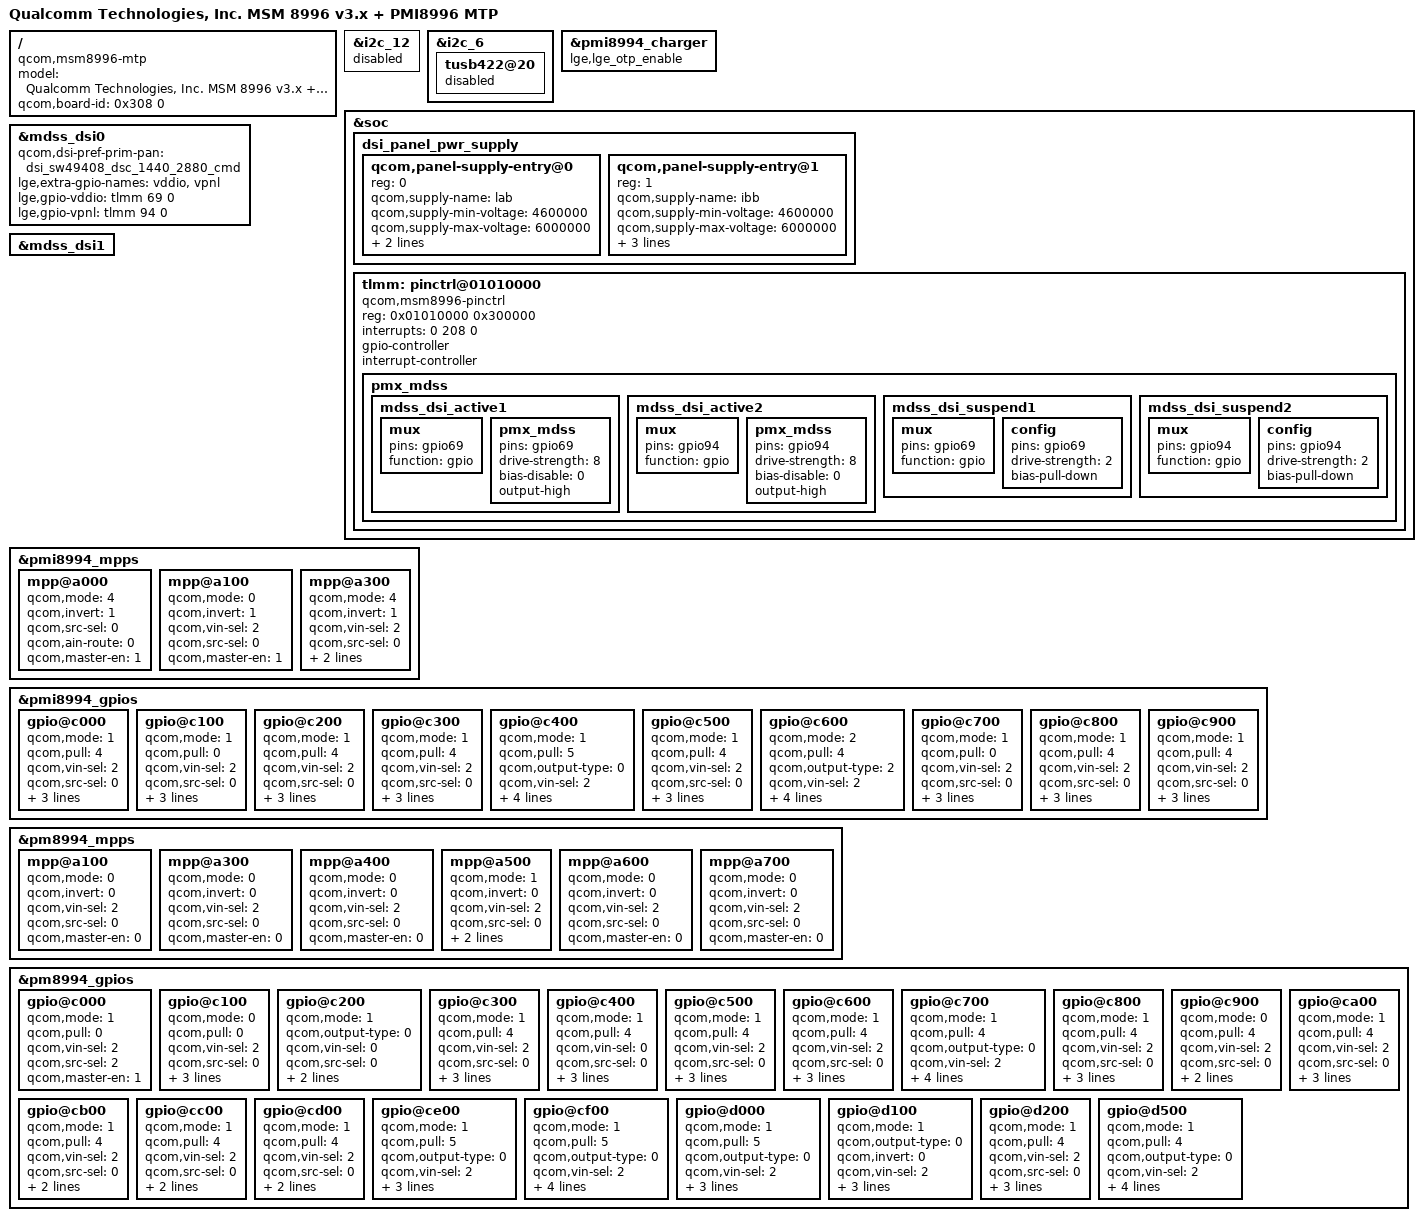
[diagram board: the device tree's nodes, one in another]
/* Copyright (c) 2015, The Linux Foundation. All rights reserved.
 *
 * This program is free software; you can redistribute it and/or modify
 * it under the terms of the GNU General Public License version 2 and
 * only version 2 as published by the Free Software Foundation.
 *
 * This program is distributed in the hope that it will be useful,
 * but WITHOUT ANY WARRANTY; without even the implied warranty of
 * MERCHANTABILITY or FITNESS FOR A PARTICULAR PURPOSE.  See the
 * GNU General Public License for more details.
 */


/dts-v1/;

#include "../../qcom/msm8996-v3.dtsi"
#include "../../qcom/msm-pmi8996.dtsi"
#include "msm8996-lucye_global_ldu.dtsi"
#include "msm8996-lucye_global_ldu-touch.dtsi"
#include "../msm8996-camera/msm8996-lucye-camera_rev-0.0.dtsi"
#include "../msm8996-lucye_storage_type/current_storage_type.dtsi"
#include "../msm8996-sound/msm8996-lucye-sound_rev-0_0.dtsi"
#include "../msm8996-lucye_sound_type/current_sound_type.dtsi"

/ {
	model = "Qualcomm Technologies, Inc. MSM 8996 v3.x + PMI8996 MTP";
	compatible = "qcom,msm8996-mtp", "qcom,msm8996", "qcom,mtp";
	qcom,board-id = <0x308 0>;
};

&i2c_12 {
	status = "disabled";
};

&i2c_6 {
	tusb422@20 {
		status = "disabled";
	};
};

&pmi8994_charger {
	/delete-property/qcom,external-typec;
	/delete-property/qcom,typec-psy-name;
};


/* Display Function */
&soc {
	dsi_panel_pwr_supply: dsi_panel_pwr_supply {
		#address-cells = <1>;
		#size-cells = <0>;

		qcom,panel-supply-entry@0 {
			reg = <0>;
			qcom,supply-name = "lab";
			qcom,supply-min-voltage = <4600000>;
			qcom,supply-max-voltage = <6000000>;
			qcom,supply-enable-load = <100000>;
			qcom,supply-disable-load = <100>;
		};

		qcom,panel-supply-entry@1 {
			reg = <1>;
			qcom,supply-name = "ibb";
			qcom,supply-min-voltage = <4600000>;
			qcom,supply-max-voltage = <6000000>;
			qcom,supply-enable-load = <100000>;
			qcom,supply-disable-load = <100>;
			qcom,supply-post-on-sleep = <20>;
		};
	};
};

&mdss_dsi0 {
	qcom,dsi-pref-prim-pan = <&dsi_sw49408_dsc_1440_2880_cmd>;
	lge,extra-gpio-names = "vddio", "vpnl";

	lge,gpio-vddio = <&tlmm 69 0>;
	lge,gpio-vpnl = <&tlmm 94 0>;
};

&mdss_dsi1 {
	/delete-property/cell-index;
};

/* pinctrl for Display function
 * GPIO69 : LCD_VDD_IO_EN
 * GPIO94 : LCD_VCL_EN
 */
&soc {
	tlmm: pinctrl@01010000 {
		compatible = "qcom,msm8996-pinctrl";
		reg = <0x01010000 0x300000>;
		interrupts = <0 208 0>;
		gpio-controller;
		#gpio-cells = <2>;
		interrupt-controller;
		#interrupt-cells = <2>;

		pmx_mdss: pmx_mdss {
			mdss_dsi_active1: mdss_dsi_active1 {
				mux {
					pins = "gpio69";
					function = "gpio";
				};

				pmx_mdss {
					pins = "gpio69";
					drive-strength = <8>; /* 8 mA */
					bias-disable = <0>; /* no pull */
					output-high;
				};
			};
			mdss_dsi_active2: mdss_dsi_active2 {
				mux {
					pins = "gpio94";
					function = "gpio";
				};

				pmx_mdss {
					pins = "gpio94";
					drive-strength = <8>; /* 8 mA */
					bias-disable = <0>; /* no pull */
					output-high;
				};
			};
			mdss_dsi_suspend1: mdss_dsi_suspend1 {
				mux {
					pins = "gpio69";
					function = "gpio";
				};

				config {
					pins = "gpio69";
					drive-strength = <2>; /* 2 mA */
					bias-pull-down; /* pull down */
				};
			};
			mdss_dsi_suspend2: mdss_dsi_suspend2 {
				mux {
					pins = "gpio94";
					function = "gpio";
				};

				config {
					pins = "gpio94";
					drive-strength = <2>; /* 2 mA */
					bias-pull-down; /* pull down */
				};
			};
		};
	};
};

&pmi8994_charger {
    lge,lge_otp_enable;
};

&pmi8994_mpps {
/* Must not define the mpp(mpp 3) on here */
	mpp@a000 {	/* MPP 1 VBACKUP_ADC */
		qcom,mode = <4>;			/* Analog input */
		qcom,invert = <1>;			/* Enable Invert */
		qcom,src-sel = <0>;			/* Constant */
		qcom,ain-route = <0>;		/* PMI AMUX ch5 */
		qcom,master-en = <1>;		/* Enable GPIO */
		status = "okay";
	};

	mpp@a100 { /* MPP 2 - FLASH_STROBE_TRIG */
		qcom,mode = <0>;			/* Digital input */
		qcom,invert = <1>;			/* Enable invert */
		qcom,vin-sel = <2>;			/* Vin 2 */
		qcom,src-sel = <0>;			/* Constant */
		qcom,master-en = <1>;		/* Enable GPIO */
		status = "okay";
	};

	mpp@a300 { /* MPP 4 - NC */
		qcom,mode = <4>;			/* Analog input */
		qcom,invert = <1>;			/* Enable Invert */
		qcom,vin-sel = <2>;			/* Vin 2 */
		qcom,src-sel = <0>;			/* Constant */
		qcom,ain_route = <1>;		/* PMI AMUX 6 */
		qcom,master-en = <0>;		/* Enable GPIO */
		status = "okay";
	};
};

&pmi8994_gpios {
	gpio@c000 { /* GPIO 1 - NC */
		qcom,mode = <1>;			/* Digital output*/
		qcom,pull = <4>;			/* Pull down 10uA */
		qcom,vin-sel = <2>;			/* VIN2 */
		qcom,src-sel = <0>;			/* Constant */
		qcom,invert = <0>;			/* Disable Invert */
		qcom,out-strength = <1>;	/* Low */
		qcom,master-en = <0>;		/* Enable GPIO */
		status = "okay";
	};

	gpio@c100 { /* GPIO 2 - NC */
		qcom,mode = <1>;			/* Digital output*/
		qcom,pull = <0>;			/* Pull down 30uA */
		qcom,vin-sel = <2>;			/* VIN2 */
		qcom,src-sel = <0>;			/* Constant */
		qcom,invert = <1>;			/* Enable Invert */
		qcom,out-strength = <1>;	/* Low */
		qcom,master-en = <0>;		/* Enable GPIO */
		status = "okay";
	};

	gpio@c200 {	/* GPIO 3 SPKR_AMP_EN2 */
		qcom,mode = <1>;			/* Digital output*/
		qcom,pull = <4>;			/* Pull down */
		qcom,vin-sel = <2>;			/* VIN2 */
		qcom,src-sel = <0>;			/* Constant */
		qcom,invert = <0>;			/* Disable Invert */
		qcom,out-strength = <1>;	/* Low */
		qcom,master-en = <1>;		/* Enable GPIO */
		status = "okay";
	};

	gpio@c300 { /* GPIO 4 - EIS_LDO_EN */
		qcom,mode = <1>;			/* Digital output*/
		qcom,pull = <4>;			/* Pull down */
		qcom,vin-sel = <2>;			/* VIN2 */
		qcom,src-sel = <0>;			/* Constant */
		qcom,invert = <0>;			/* Disable Invert */
		qcom,out-strength = <1>;	/* Low */
		qcom,master-en = <1>;		/* Enable GPIO */
		status = "okay";
	};

	gpio@c400 { /* GPIO 5 - NC */
		qcom,mode = <1>;			/* Digital output*/
		qcom,pull = <5>;			/* No pull */
		qcom,output-type = <0>;		/* CMOS logic */
		qcom,vin-sel = <2>;			/* VIN2 */
		qcom,src-sel = <0>;			/* Constant */
		qcom,invert = <0>;			/* Enable Invert */
		qcom,out-strength = <2>;	/* Low */
		qcom,master-en = <0>;		/* Enable GPIO */
		status = "okay";
	};

	gpio@c500 { /* GPIO 6 - NC */
		qcom,mode = <1>;			/* Digital input */
		qcom,pull = <4>;			/* Pull down */
		qcom,vin-sel = <2>;			/* VIN2 */
		qcom,src-sel = <0>;			/* Constant */
		qcom,invert = <0>;			/* Disable Invert */
		qcom,out-strength = <1>;	/* Low */
		qcom,master-en = <0>;		/* Enable GPIO */
		status = "okay";
	};

	gpio@c600 { /* GPIO 7 - NC */
		qcom,mode = <2>;		/* Digital in & output*/
		qcom,pull = <4>;			/* No Pull */
		qcom,output-type = <2>;			/* Open Low */
		qcom,vin-sel = <2>;			/* VIN2 */
		qcom,src-sel = <0>;			/* Constant */
		qcom,invert = <0>;			/* Enable invert */
		qcom,out-strength = <2>;	/* Low */
		qcom,master-en = <0>;		/* Enable GPIO */
		status = "okay";
	};

	gpio@c700 { /* GPIO 8 - NC */
		qcom,mode = <1>;			/* Digital output*/
		qcom,pull = <0>;			/* Pull up */
		qcom,vin-sel = <2>;			/* VIN2 */
		qcom,src-sel = <0>;			/* Constant */
		qcom,invert = <1>;			/* Enable Invert */
		qcom,out-strength = <1>;	/* Low */
		qcom,master-en = <0>;		/* Enable GPIO */
		status = "okay";
	};

	gpio@c800 { /* GPIO 9 - NC */
		qcom,mode = <1>;			/* Digital output */
		qcom,pull = <4>;			/* Pull down */
		qcom,vin-sel = <2>;			/* Vin 2 */
		qcom,src-sel = <0>;			/* Constant */
		qcom,invert = <0>;			/* Disable Invert */
		qcom,out-strength = <1>;	/* Low */
		qcom,master-en = <0>;		/* Enable GPIO */
		status = "okay";
	};

	gpio@c900 { /* GPIO 10 - NC */
		qcom,mode = <1>;			/* Digital output */
		qcom,pull = <4>;			/* Pull down */
		qcom,vin-sel = <2>;			/* Vin 2 */
		qcom,src-sel = <0>;			/* Constant */
		qcom,invert = <0>;			/* Disable Invert */
		qcom,out-strength = <1>;	/* Low */
		qcom,master-en = <0>;		/* Enable GPIO */
		status = "okay";
	};
};

&pm8994_mpps {
/* Must not define the mpps(mpp 1 and 3) on here */
	mpp@a100 { /* MPP 2 - NC */
		qcom,mode = <0>;			/* Digital input */
		qcom,invert = <0>;			/* Diable invert */
		qcom,vin-sel = <2>;			/* Vin 2 */
		qcom,src-sel = <0>;			/* Constant */
		qcom,master-en = <0>;		/* Disable GPIO */
		status = "okay";
	};

	mpp@a300 { /* MPP 4 - NC */
		qcom,mode = <0>;			/* Digital input */
		qcom,invert = <0>;			/* Diable invert */
		qcom,vin-sel = <2>;			/* Vin 2 */
		qcom,src-sel = <0>;			/* Constant */
		qcom,master-en = <0>;		/* Disable GPIO */
		status = "okay";
	};

	mpp@a400 { /* MPP 5 - NC */
		qcom,mode = <0>;			/* Digital input */
		qcom,invert = <0>;			/* Diable invert */
		qcom,vin-sel = <2>;			/* Vin 2 */
		qcom,src-sel = <0>;			/* Constant */
		qcom,master-en = <0>;		/* Disable GPIO */
		status = "okay";
	};

	mpp@a500 { /* MPP 6 - STAT_SMB1350 */
		qcom,mode = <1>;			/* Digital output */
		qcom,invert = <0>;			/* Enable invert */
		qcom,vin-sel = <2>;			/* Vin 2 */
		qcom,src-sel = <0>;			/* Constant */
		qcom,out-strength = <1>;	/* Low */
		qcom,master-en = <1>;		/* Disable GPIO */
		status = "okay";
	};

	mpp@a600 { /* MPP 7 - NC */
		qcom,mode = <0>;			/* Digital input */
		qcom,invert = <0>;			/* Diable invert */
		qcom,vin-sel = <2>;			/* Vin 2 */
		qcom,src-sel = <0>;			/* Constant */
		qcom,master-en = <0>;		/* Disable GPIO */
		status = "okay";

	};

	mpp@a700 { /* MPP 8 - NC */
		qcom,mode = <0>;			/* Analog input */
		qcom,invert = <0>;			/* Enable Invert */
		qcom,vin-sel = <2>;			/* Vin 2 */
		qcom,src-sel = <0>;			/* Constant */
		qcom,master-en = <0>;		/* Disable GPIO */
		status = "okay";
	};
};

&pm8994_gpios {
/* Must not define the gpios(gpio 20 and 21) on here */
	gpio@c000 { /* GPIO 1 VCONN */
		qcom,mode = <1>;		/* Digital output */
		qcom,pull = <0>;
		qcom,vin-sel = <2>;		/* VIN2 */
		qcom,src-sel = <2>;		/* GPIO */
		qcom,master-en = <1>;		/* Enable GPIO */
		status = "okay";
	};

	gpio@c100 { /* GPIO 2 - VOL_UP_EN */
		qcom,mode = <0>;			/* Digital input */
		qcom,pull = <0>;			/* Pull up 30uA */
		qcom,vin-sel = <2>;			/* Vin 2 */
		qcom,src-sel = <0>;			/* Constant */
		qcom,invert = <1>;			/* Enable Invert */
		qcom,out-strength = <1>;	/* Low */
		qcom,master-en = <1>;		/* Enable GPIO */
		status = "okay";
	};

	gpio@c200 { /* GPIO 3 SBU_SEL */
		qcom,mode = <1>;		/* Digital output */
		qcom,output-type = <0>;		/* MOS logic */
		qcom,vin-sel = <0>;		/* VPH_PWR */
		qcom,src-sel = <0>;		/* Constant */
		qcom,out-strength = <1>;	/* High drive strength */
		qcom,master-en = <1>;		/* Enable GPIO */
		status = "okay";
	};

	gpio@c300 { /* GPIO 4 - NC */
		qcom,mode = <1>;			/* Digital output */
		qcom,pull = <4>;			/* Pull down */
		qcom,vin-sel = <2>;			/* Vin 2 */
		qcom,src-sel = <0>;			/* Constant */
		qcom,invert = <0>;			/* Disable Invert */
		qcom,out-strength = <1>;	/* Low */
		qcom,master-en = <0>;		/* Enable GPIO */
		status = "okay";
	};

	gpio@c400 { /* GPIO 5 - SWAP_CTRL_EN1 */
		qcom,mode = <1>;			/* Digital output */
		qcom,pull = <4>;			/* Pull down */
		qcom,vin-sel = <0>;			/* Vin 0 */
		qcom,src-sel = <0>;			/* Constant */
		qcom,invert = <0>;			/* Disable Invert */
		qcom,out-strength = <2>;	/* Middle */
		qcom,master-en = <1>;		/* Enable GPIO */
		status = "okay";
	};

	gpio@c500 { /* GPIO 6 - MENU_KEY_TOUCH_PM -> 16M_AVDD_EN */
		qcom,mode = <1>;			/* Digital output */
		qcom,pull = <4>;			/* Pull down */
		qcom,vin-sel = <2>;			/* Vin 2 */
		qcom,src-sel = <0>;			/* Constant */
		qcom,invert = <0>;			/* Disable Invert */
		qcom,out-strength = <1>;	/* Low */
		qcom,master-en = <1>;		/* Enable GPIO */
		status = "okay";
	};

	gpio@c600 { /* GPIO 7 - BACK_KEY_TOUCH_PM -> 8M_AVDD_EN */
		qcom,mode = <1>;			/* Digital output */
		qcom,pull = <4>;			/* Pull down */
		qcom,vin-sel = <2>;			/* Vin 2 */
		qcom,src-sel = <0>;			/* Constant */
		qcom,invert = <0>;			/* Disable Invert */
		qcom,out-strength = <1>;	/* Low */
		qcom,master-en = <1>;		/* Enable GPIO */
		status = "okay";
	};

	gpio@c700 { /* GPIO 8 - WLAN_POWER_EN */
		qcom,mode = <1>;			/* Digital output */
		qcom,pull = <4>;			/* Pull down */
		qcom,output-type = <0>;		/* CMOS logic */
		qcom,vin-sel = <2>;			/* Vin2 */
		qcom,src-sel = <0>;			/* Constant */
		qcom,invert = <0>;			/* Disable Invert */
		qcom,out-strength = <1>;	/* Low */
		qcom,master-en = <1>;		/* Enable GPIO */
		status = "okay";
	};

	gpio@c800 { /* GPIO 9 - MME_DCDC_EN */
		qcom,mode = <1>;            /* Digital output */
		qcom,pull = <4>;            /* Pull down */
		qcom,vin-sel = <2>;         /* Vin 2 */
		qcom,src-sel = <0>;         /* Constant */
		qcom,invert = <0>;          /* Disable Invert */
		qcom,out-strength = <1>;    /* Low */
		qcom,master-en = <1>;		/* Enable GPIO */
		status = "okay";
	};

	gpio@c900 { /* GPIO 10 - NC */
		qcom,mode = <0>;			/* Digital input */
		qcom,pull = <4>;			/* Pull down */
		qcom,vin-sel = <2>;			/* Vin 2 */
		qcom,src-sel = <0>;			/* Constant */
		qcom,invert = <0>;			/* Disable Invert */
		qcom,master-en = <0>;		/* Disable GPIO */
		status = "okay";
	};

	gpio@ca00 { /* GPIO 11 - NC */
		qcom,mode = <1>;			/* Digital output */
		qcom,pull = <4>;			/* Pull down */
		qcom,vin-sel = <2>;			/* Vin 2 */
		qcom,src-sel = <0>;			/* Constant */
		qcom,invert = <0>;			/* Invert */
		qcom,out-strength = <1>;	/* Low */
		qcom,master-en = <0>;		/* Enable GPIO */
		status = "okay";
	};

	gpio@cb00 { /* GPIO 12 - MME GPIO_SLEEP_N */
		qcom,mode = <1>;            /* Digital output */
		qcom,pull = <4>;            /* Pull down */
		qcom,vin-sel = <2>;         /* Vin 2 */
		qcom,src-sel = <0>;         /* Constant */
		qcom,invert = <0>;          /* Disable Invert */
		qcom,master-en = <1>;		/* Enable GPIO */
		status = "okay";
	};

	gpio@cc00 { /* GPIO 13 - MME GPIO_PH */
		qcom,mode = <1>;            /* Digital output */
		qcom,pull = <4>;            /* Pull down */
		qcom,vin-sel = <2>;         /* Vin 2 */
		qcom,src-sel = <0>;         /* Constant */
		qcom,invert = <0>;          /* Disable Invert */
		qcom,master-en = <1>;		/* Enable GPIO */
		status = "okay";
	};

	gpio@cd00 { /* GPIO 14 - MME GPIO_EN  */
		qcom,mode = <1>;            /* Digital output */
		qcom,pull = <4>;            /* Pull down */
		qcom,vin-sel = <2>;         /* Vin 2 */
		qcom,src-sel = <0>;         /* Constant */
		qcom,invert = <0>;          /* Disable Invert */
		qcom,master-en = <1>;		/* Enable GPIO */
		status = "okay";
	};

	gpio@ce00 { /* GPIO 15 - CODEC_MCLK */
		qcom,mode = <1>;			/* Digital output */
		qcom,pull = <5>;			/* No pull */
		qcom,output-type = <0>;		/* CMOS logic */
		qcom,vin-sel = <2>;			/* Vin 2 */
		qcom,src-sel = <2>;			/* Function 2 */
		qcom,out-strength = <2>;	/* Middle */
		qcom,master-en = <1>;		/* Enable GPIO */
		status = "okay";
	};

	gpio@cf00 { /* GPIO 16 - PMI_CLK_IN */
		qcom,mode = <1>;			/* Digital output */
		qcom,pull = <5>;			/* No pull */
		qcom,output-type = <0>;		/* CMOS logic */
		qcom,vin-sel = <2>;			/* Vin 2 */
		qcom,src-sel = <2>;			/* Function 2 */
		qcom,invert = <0>;			/* Disable Invert */
		qcom,out-strength = <3>;	/* High */
		qcom,master-en = <1>;		/* Enable GPIO */
		status = "okay";
	};

	gpio@d000 { /* GPIO 17 - AOD_RTC */
		qcom,mode = <1>;			/* Digital output */
		qcom,pull = <5>;			/* No pull */
		qcom,output-type = <0>;		/* CMOS logic */
		qcom,vin-sel = <2>;			/* Vin 2 */
		qcom,src-sel = <3>;			/* Function 2 */
		qcom,out-strength = <2>;	/* Middle */
		qcom,master-en = <1>;		/* Enable GPIO */
		status = "okay";
	};

	gpio@d100 { /* GPIO 18 - WIFI_SLEEP_CLK */
		qcom,mode = <1>;			/* Digital output */
		qcom,output-type = <0>;		/* CMOS logic */
		qcom,invert = <0>;			/* Output low initially */
		qcom,vin-sel = <2>;			/* VIN 2 */
		qcom,src-sel = <3>;			/* Function 2 */
		qcom,out-strength = <2>;	/* Medium */
		qcom,master-en = <1>;		/* Enable GPIO */
		status = "okay";
	};

	gpio@d200 { /* GPIO 19 - BT_POWER_ON */
		qcom,mode = <1>;			/* Digital output */
		qcom,pull = <4>;			/* Pull down */
		qcom,vin-sel = <2>;			/* Vin2 */
		qcom,src-sel = <0>;			/* Constant */
		qcom,invert = <0>;			/* Disable Invert */
		qcom,out-strength = <1>;	/* Low */
		qcom,master-en = <1>;		/* Enable GPIO */
		status = "okay";
	};
	
	gpio@d500 { /* GPIO 22 - NC */
		qcom,mode = <1>;			/* Digital output */
		qcom,pull = <4>;			/* Pull down */
		qcom,output-type = <0>;		/* CMOS logic */
		qcom,vin-sel = <2>;			/* Vin 2 */
		qcom,src-sel = <0>;			/* Constant */
		qcom,invert = <0>;			/* Disable Invert */
		qcom,out-strength = <1>;	/* Low */
		qcom,master-en = <0>;		/* Enable GPIO */
		status = "okay";
	};
};
